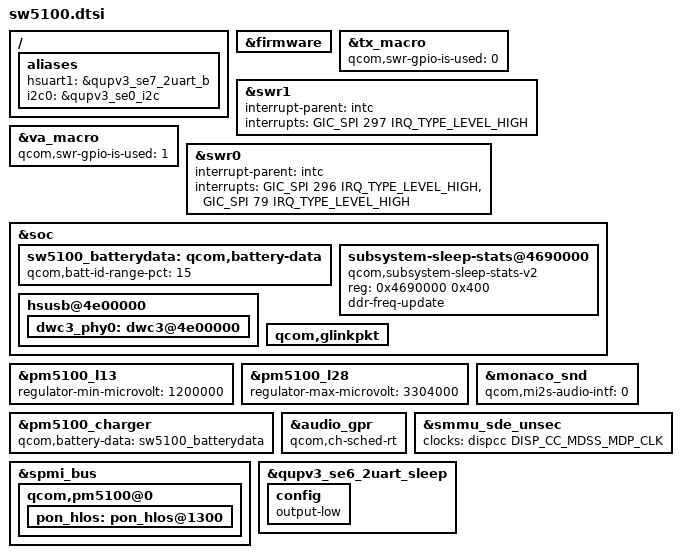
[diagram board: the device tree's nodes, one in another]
// SPDX-License-Identifier: GPL-2.0
// base on: monaco.dtsi

#include "../vendor/qcom/monaco.dtsi"
#include "../data-devicetree/monaco-ipa.dtsi"
#include "../dsp-devicetree/monaco/monaco-dsp.dtsi"
#include "../audio-devicetree/monaco-audio.dtsi"
#include "../audio-devicetree/monaco-audio-overlay.dtsi"
#include "../video-devicetree/monaco-vidc.dtsi"
#include "../graphics-devicetree/gpu/monaco-gpu.dtsi"
#include "../display-devicetree/display/monaco-sde-display.dtsi"
#include "sw5100-i2s.dtsi"
#include "sw5100-pinctrl.dtsi"
#include "sw5100-qupv3.dtsi"
#include "sw5100-sdhc.dtsi"
#include "sw5100-glinkpkt.dtsi"

/ {
	aliases: aliases {
		hsuart1 = &qupv3_se7_2uart_b;
		i2c0 = &qupv3_se0_i2c;
	};
};

&firmware {
	/delete-node/ android;
};

&tx_macro {
	/delete-property/ qcom,is-used-swr-gpio;
	qcom,swr-gpio-is-used = <0>;
};

&swr1 {
	interrupt-parent = <&intc>;
	interrupts = <GIC_SPI 297 IRQ_TYPE_LEVEL_HIGH>;
};

&va_macro {
	/delete-property/ qcom,is-used-swr-gpio;
	qcom,swr-gpio-is-used = <1>;
};

&swr0 {
	interrupt-parent = <&intc>;
	interrupts =
		<GIC_SPI 296 IRQ_TYPE_LEVEL_HIGH>,
		<GIC_SPI 79 IRQ_TYPE_LEVEL_HIGH>;
};

&soc {
	/delete-node/ qcom,battery-data;

	sw5100_batterydata: qcom,battery-data {
		qcom,batt-id-range-pct = <15>;
	};

	subsystem-sleep-stats@4690000 {
		compatible = "qcom,subsystem-sleep-stats-v2";
		reg = <0x4690000 0x400>;
		ddr-freq-update;
	};

};

&pm5100_l13 {
	regulator-min-microvolt = <1200000>;
};

&pm5100_l28 {
	regulator-max-microvolt = <3304000>;
};

&pm5100_charger {
	qcom,battery-data = <&sw5100_batterydata>;
	/delete-property/ qcom,fcc-stepping-enable;
	/delete-property/ qcom,fcc-step-delay-ms;
	/delete-property/ qcom,fcc-step-size-ua;
	/delete-property/ qcom,fcc-step-start-ua;
};

&monaco_snd {
	/delete-property/ qcom,cdc-dmic01-gpios;
	/delete-property/ qcom,cdc-dmic23-gpios;

	qcom,mi2s-audio-intf = <0>;
};

// TODO: b/436905592 - Delete once qcom patch lands in monaco-audio.dtsi.
&audio_gpr {
	qcom,ch-sched-rt;
};

// TODO: b/300099373 - Delete once qcom patch lands setting this in monaco
&smmu_sde_unsec {
	clocks = <&dispcc DISP_CC_MDSS_MDP_CLK>;
	clock-names = "mdp_core_clk";
};

&spmi_bus {
    qcom,pm5100@0 {
        pon_hlos: pon_hlos@1300 {
        };
    };
};

&soc {
	hsusb@4e00000 {
		dwc3_phy0: dwc3@4e00000 {
		};
	};
};

&qupv3_se6_2uart_sleep {
	config {
		output-low;
	};
};

&soc {
	qcom,glinkpkt {
		/delete-node/ qcom,glinkpkt-slate-ssc-hal;
		/delete-node/ qcom,glinkpkt-slate-sso-hal;
		/delete-node/ qcom,glinkpkt-slate-cam-hal;
		/delete-node/ qcom,glinkpkt-slate-display-ctrl;
		/delete-node/ qcom,glinkpkt-slate-location-ctrl;
		/delete-node/ qcom,glinkpkt-slate-display-data;
		/delete-node/ qcom,glinkpkt-slate-touch-ctrl;
		/delete-node/ qcom,glinkpkt-slate-ssc-usta;
		/delete-node/ qcom,glinkpkt-slate-ssc-test-0;
		/delete-node/ qcom,glinkpkt-slate-ssc-test-1;
		/delete-node/ qcom,glinkpkt-slate-ssc-test-2;
		/delete-node/ qcom,glinkpkt-slate-ssc-test-3;
		/delete-node/ qcom,glinkpkt-slate-ssc-test-4;
		/delete-node/ qcom,glinkpkt-slate-ssc-test-5;
		/delete-node/ qcom,glinkpkt-slate-ssc-test-6;
		/delete-node/ qcom,glinkpkt-slate-ssc-test-7;
		/delete-node/ qcom,glinkpkt-slate-ssc-test-8;
		/delete-node/ qcom,glinkpkt-slate-ssc-test-9;
		/delete-node/ qcom,glinkpkt-slate-ssc-test-10;
		/delete-node/ qcom,glinkpkt-slate-ssc-test-11;
		/delete-node/ qcom,glinkpkt-slate-ssc-test-12;
		/delete-node/ qcom,glinkpkt-slate-ssc-test-13;
		/delete-node/ qcom,glinkpkt-slate-ssc-test-14;
		/delete-node/ qcom,glinkpkt-slate-apps-diag-cntl;
		/delete-node/ qcom,glinkpkt-slate-apps-diag-cmd;
		/delete-node/ qcom,glinkpkt-slate-apps-diag-data;
		/delete-node/ qcom,glinkpkt-slate-adsp-diag-cntl;
		/delete-node/ qcom,glinkpkt-slate-adsp-diag-cmd;
		/delete-node/ qcom,glinkpkt-slate-adsp-diag-data;
		/delete-node/ qcom,glinkpkt-slate-tme-data;
		/delete-node/ qcom,glinkpkt-haptics-offload-ctrl;
		/delete-node/ qcom,glinkpkt-slate-ux-ctl;
		/delete-node/ qcom,glinkpkt-slate-qcli;
		/delete-node/ qcom,glinkpkt-slate-bt-ctrl;
		/delete-node/ qcom,glinkpkt-bt-offload-event;
		/delete-node/ qcom,glinkpkt-bt-app-offload-data;
		/delete-node/ qcom,glinkpkt-slate-dfu;
		/delete-node/ qcom,glinkpkt-slate-custom-data;
		/delete-node/ qcom,glinkpkt-ss-bt-ctrl;
		/delete-node/ qcom,glinkpkt-ss-bt-data;
		/delete-node/ qcom,glinkpkt-ss-bt-le-data;
		/delete-node/ qcom,glinkpkt-ss-bt-ssr-data;
		/delete-node/ qcom,glinkpkt-ss-bt-obex-data;
	};
};
